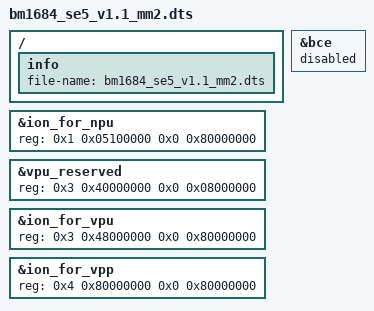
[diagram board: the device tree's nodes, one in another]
#include "bm1684_se5_v1.1.dts"

/ {
	info {
		file-name = "bm1684_se5_v1.1_mm2.dts"; // for cust01
	};
};

&bce {
	status = "disabled"; // to avoid slow ipsec problem
};

&ion_for_npu {
	reg = <0x1 0x05100000 0x0 0x80000000>; // 2G, for NPU
};

&vpu_reserved {
	reg = <0x3 0x40000000 0x0 0x08000000>; // 128M, for VPU firmware
};

&ion_for_vpu {
	reg = <0x3 0x48000000 0x0 0x80000000>; // 2G, for VPU
};

&ion_for_vpp {
	reg = <0x4 0x80000000 0x0 0x80000000>; // 2G, for VPP/JPU
};
